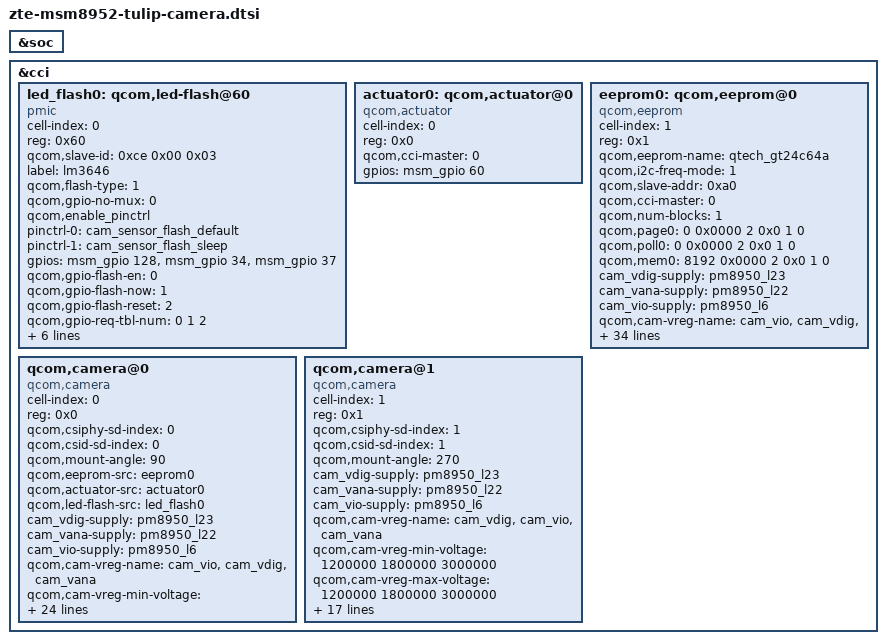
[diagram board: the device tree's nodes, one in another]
/*
 * Copyright (c) 2015, The Linux Foundation. All rights reserved.
 *
 * This program is free software; you can redistribute it and/or modify
 * it under the terms of the GNU General Public License version 2 and
 * only version 2 as published by the Free Software Foundation.
 *
 * This program is distributed in the hope that it will be useful,
 * but WITHOUT ANY WARRANTY; without even the implied warranty of
 * MERCHANTABILITY or FITNESS FOR A PARTICULAR PURPOSE.  See the
 * GNU General Public License for more details.
 */



&soc {

};

&cci {
	led_flash0: qcom,led-flash@60 {
			cell-index = <0>;
			reg = <0x60>;
			qcom,slave-id = <0xce 0x00 0x03>;
			compatible = "pmic";
			//compatible = "qcom-flash,lm3642";
			label = "lm3646";
			qcom,flash-type = <1>;
			qcom,gpio-no-mux = <0>;
			qcom,enable_pinctrl;
			pinctrl-names = "cam_flash_default", "cam_flash_suspend";
			pinctrl-0 = <&cam_sensor_flash_default>;
			pinctrl-1 = <&cam_sensor_flash_sleep>;
			//33- flash_en
			//34-flash_strobe_now
			//37 flash_torch_lm
			gpios = <&msm_gpio 128 0>,//128
					<&msm_gpio 34 0>,
					<&msm_gpio 37 0>;
			qcom,gpio-flash-en = <0>;
			qcom,gpio-flash-now = <1>;
			qcom,gpio-flash-reset = <2>;
			qcom,gpio-req-tbl-num = <0 1 2>;
			qcom,gpio-req-tbl-flags = <0 0 0>;
				 qcom,gpio-req-tbl-label = "FLASH_EN",
									  "FLASH_NOW",
									  "FLASH_RSTcdp";

			qcom,cci-master = <0>;
			cam_vio-supply = <&pm8950_l6>;
			qcom,cam-vreg-name = "cam_vio";
			//qcom,cam-vreg-type = <1>;
};

	actuator0: qcom,actuator@0 {
		cell-index = <0>;
		reg = <0x0>;
		compatible = "qcom,actuator";
		qcom,cci-master = <0>;
		gpios = <&msm_gpio 60 0>;
	};


	eeprom0: qcom,eeprom@0 {
		cell-index = <1>;
		reg = <0x1>;
			qcom,eeprom-name = "qtech_gt24c64a";
		compatible = "qcom,eeprom";
			qcom,i2c-freq-mode = <1>;
			qcom,slave-addr = <0xa0>;
		qcom,cci-master = <0>;
			qcom,num-blocks = <1>;
			qcom,page0	 = <0 0x0000 2 0x0 1 0>;
			qcom,poll0	 = <0 0x0000 2 0x0 1 0>;
			qcom,mem0	 = <8192 0x0000 2 0x0 1 0>;
		cam_vdig-supply = <&pm8950_l23>;
		cam_vana-supply = <&pm8950_l22>;
		cam_vio-supply = <&pm8950_l6>;
			qcom,cam-vreg-name =  "cam_vio", "cam_vdig","cam_vana";
			qcom,cam-vreg-min-voltage = <1800000 1200000 2800000>;
			qcom,cam-vreg-max-voltage = <1800000 1200000 2850000>;
			qcom,cam-vreg-op-mode = <200000 200000 100000>;
		pinctrl-names = "cam_default", "cam_suspend";
		pinctrl-0 = <&cam_sensor_mclk0_default
				&cam_sensor_rear_default>;
		pinctrl-1 = <&cam_sensor_mclk0_sleep &cam_sensor_rear_sleep>;
		gpios = <&msm_gpio 26 0>,
			<&msm_gpio 36 0>,
				<&msm_gpio 35 0>,
				<&msm_gpio 63 0>,
				<&msm_gpio 60 0>;
		qcom,gpio-reset = <1>;
		qcom,gpio-standby = <2>;
			qcom,gpio-vdig = <3>;
			qcom,gpio-vaf = <4>;
			qcom,gpio-req-tbl-num = <0 1 2 3 4 >;
			qcom,gpio-req-tbl-flags = <1 0 0 0 0 >;
		qcom,gpio-req-tbl-label = "CAMIF_MCLK0",
			"CAM_RESET0",
				"CAM_STANDBY0",
				"CAM_VDIG0",
				"CAM_VAF0";
			qcom,cam-power-seq-type = "sensor_gpio", "sensor_vreg", "sensor_vreg",
				"sensor_vreg", "sensor_clk", "sensor_gpio", "sensor_gpio", "sensor_gpio";
			qcom,cam-power-seq-val ="sensor_gpio_reset",  "cam_vdig", "cam_vana", "cam_vio",
				"sensor_cam_mclk", "sensor_gpio_vdig", "sensor_gpio_vaf", "sensor_gpio_reset";
			qcom,cam-power-seq-cfg-val = <0 0 0 0 24000000 1 1 1>;
			qcom,cam-power-seq-delay = <1 0 0 0 1 0 0 10>;
		clocks = <&clock_gcc clk_mclk0_clk_src>,
				<&clock_gcc clk_gcc_camss_mclk0_clk>;
		clock-names = "cam_src_clk", "cam_clk";

	};

	qcom,camera@0 {
		cell-index = <0>;
		compatible = "qcom,camera";
		reg = <0x0>;
		qcom,csiphy-sd-index = <0>;
		qcom,csid-sd-index = <0>;
		qcom,mount-angle = <90>;
		qcom,eeprom-src = <&eeprom0 >;
		qcom,actuator-src = <&actuator0>;
		qcom,led-flash-src = <&led_flash0>;
		cam_vdig-supply = <&pm8950_l23>;
		cam_vana-supply = <&pm8950_l22>;
		cam_vio-supply = <&pm8950_l6>;
		qcom,cam-vreg-name =  "cam_vio", "cam_vdig","cam_vana";
							//"cam_vaf";
		qcom,cam-vreg-min-voltage = <1800000 1200000 3000000>;
		qcom,cam-vreg-max-voltage = <1800000 1200000 3000000>;
		qcom,cam-vreg-op-mode = <200000 200000 100000>;
		pinctrl-names = "cam_default", "cam_suspend";
		pinctrl-0 = <&cam_sensor_mclk0_default
				&cam_sensor_rear_default>;
		pinctrl-1 = <&cam_sensor_mclk0_sleep &cam_sensor_rear_sleep>;
		gpios = <&msm_gpio 26 0>,
			<&msm_gpio 36 0>,
			<&msm_gpio 35 0>,
		<&msm_gpio 63 0>,
		<&msm_gpio 60 0>;
		qcom,gpio-reset = <1>;
		qcom,gpio-standby = <2>;
		qcom,gpio-vdig = <3>;
		qcom,gpio-vaf = <4>;
		qcom,gpio-req-tbl-num = <0 1 2 3 4 >;
		qcom,gpio-req-tbl-flags = <1 0 0 0 0 >;
		qcom,gpio-req-tbl-label = "CAMIF_MCLK0",
			"CAM_RESET0",
			"CAM_STANDBY0",
			"CAM_VDIG0",
		       "CAM_VAF0";
		qcom,sensor-position = <0>;
		qcom,sensor-mode = <0>;
		qcom,cci-master = <0>;
		status = "ok";
		clocks = <&clock_gcc clk_mclk0_clk_src>,
				<&clock_gcc clk_gcc_camss_mclk0_clk>;
		clock-names = "cam_src_clk", "cam_clk";
	};

	qcom,camera@1 {
		cell-index = <1>;
		compatible = "qcom,camera";
		reg = <0x1>;
		qcom,csiphy-sd-index = <1>;
		qcom,csid-sd-index = <1>;
		qcom,mount-angle = <270>;
		//qcom,eeprom-src = <&eeprom1>;
		cam_vdig-supply = <&pm8950_l23>;
		cam_vana-supply = <&pm8950_l22>;
		cam_vio-supply = <&pm8950_l6>;
		//cam_vaf-supply = <&pm8950_l17>;
		qcom,cam-vreg-name = "cam_vdig", "cam_vio", "cam_vana";

		qcom,cam-vreg-min-voltage = <1200000 1800000 3000000 >;
		qcom,cam-vreg-max-voltage = <1200000 1800000 3000000>;
		qcom,cam-vreg-op-mode = <200000  80000 100000>;
		pinctrl-names = "cam_default", "cam_suspend";
		pinctrl-0 = <&cam_sensor_mclk2_default &cam_sensor_front1_default>;
		pinctrl-1 = <&cam_sensor_mclk2_sleep &cam_sensor_front1_sleep>;
		gpios = <&msm_gpio 28 0>,
			<&msm_gpio 40 0>,
			<&msm_gpio 60 0>;
		qcom,gpio-reset = <1>;
		qcom,gpio-vana = <2>;

		qcom,gpio-req-tbl-num = <0 1 2>;
		qcom,gpio-req-tbl-flags = <1 0 0>;
		qcom,gpio-req-tbl-label = "CAMIF_MCLK1",
			"CAM_RESET1",
			"CAM_VANA1";
		qcom,sensor-position = <1>;
		qcom,sensor-mode = <0>;
		qcom,cci-master = <0>;
		status = "ok";
		clocks = <&clock_gcc clk_mclk2_clk_src>,
			<&clock_gcc clk_gcc_camss_mclk2_clk>;
		clock-names = "cam_src_clk", "cam_clk";
	};

};
